# A34M41x register map
Vendor: ABOV Semiconductor Co., Ltd.; File version: 1.0
CPU: CM4 r0p1, little endian, MPU, FPU, VTOR, 4 interrupt priority bits
Registers are 32-bit, read-write, reset 0x0 unless marked. A register's access mark holds for its fields unless they carry their own. Offsets are from the block's base; [hi:lo] are bit positions; {n}, {i} and the like mark numbered series.

## CHIPCONFIG — Chip Configuration Data
Base 0x4000F000
0x00 VENDORID ro reset 0x41424F56
0x04 CHIPID ro
0x08 REVNR ro — Revision Number Register

## PA — General Port A
Base 0x40001000
Same registers: PB 0x40001100, PC 0x40001200, PD 0x40001300, PE 0x40001400, PF 0x40001500, PG 0x40001600
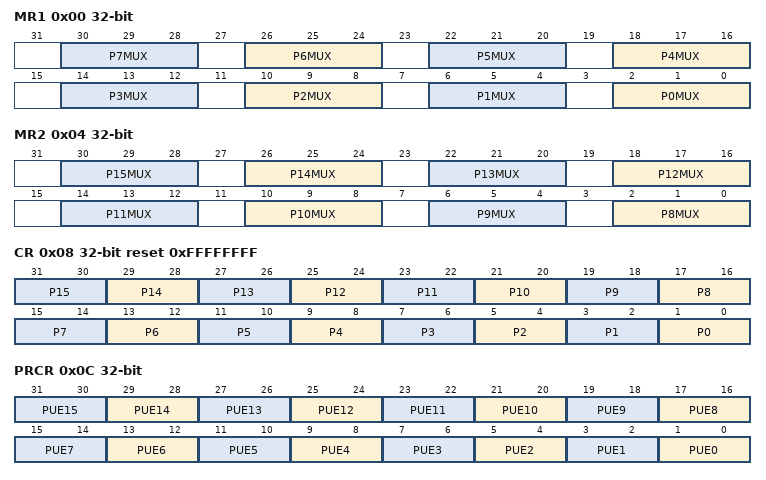
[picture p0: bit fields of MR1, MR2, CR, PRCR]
0x00 MR1 — Port n MUX1 Selection Register
  [4n+2:4n] P{n}MUX (n=0..7) — Pin {n} Mode Selection bits
0x04 MR2 — Port n MUX2 Selection Register
  [4n-30:4n-32] P{n}MUX (n=8..15) — Pin {n} Mode Selection bits
0x08 CR reset 0xFFFFFFFF — Port n Type Selection Register
  [2n+1:2n] P{n} (n=0..15) — Pin {n} Type Selection bit
0x0C PRCR — Port n Pull-up/down Selection Register
  [2n+1:2n] PUE{n} (n=0..15) — Pin {n} Pull-up/down Selection bits
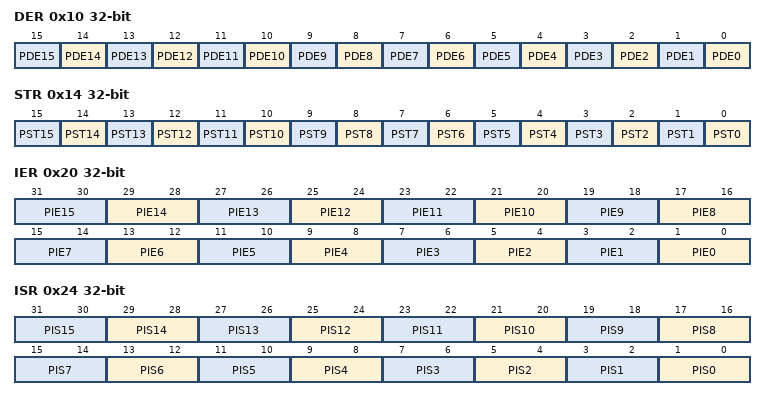
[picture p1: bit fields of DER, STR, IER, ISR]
0x10 DER — Port n Debounce Enable Register
  [n] PDE{n} (n=0..15) — Pin {n} Debounce Enable bits
0x14 STR — Port n Strength Selection Register
  [n] PST{n} (n=0..15) — Pin {n} Strength Selection bit
0x20 IER — Port n Interrupt Enable Register
  [2n+1:2n] PIE{n} (n=0..15) — Pin {n} Interrupt Enable bit
0x24 ISR — Port n Interrupt Status Register
  [2n+1:2n] PIS{n} (n=0..15) — Pin {n} Interrupt Status bit
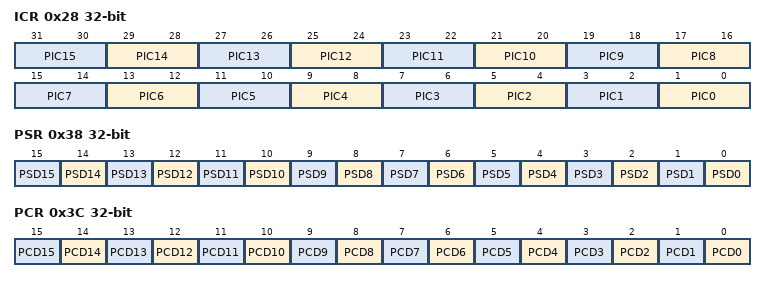
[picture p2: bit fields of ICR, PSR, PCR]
0x28 ICR — Port n Interrupt Control Register
  [2n+1:2n] PIC{n} (n=0..15) — Pin {n} Interrupt Control bit
0x30 ODR — Port n Output Data Register
  [15:0] POD — Pin Output Data bit
0x34 IDR ro — Port n Input Data Register
  [15:0] PID — Port Input Data bits
0x38 PSR wo — Port n Data Set Register
  [n] PSD{n} (n=0..15) — Port {n} Data Set bits
0x3C PCR wo — Port n Data Clear Register
  [n] PCD{n} (n=0..15) — Port {n} Data Clear bits

## PORTEN — General Port Access Enable
Base 0x40001FF0
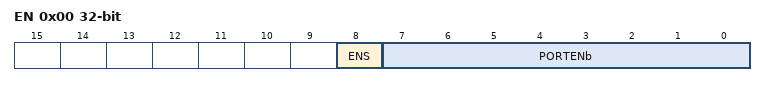
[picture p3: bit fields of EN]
0x00 EN wo (reset mask 0xFF) — Port Access Enable Register
  [8] ENS ro — Enable Status Bit
  [7:0] PORTENb — Port Access Enable bit, write sequence 0x15, 0x51

## DFMC — DATA FLASH MEMORY CONTROLLER
Base 0x41001000
0x00 CONF — Flash Memory Control Register
  [3:0] LATENCY — Flash Wait Value Bits
0x04 FLSKEY — Flash Memory Access Key Register
  [31:0] FKEY — Flash Memory Access Key, KEY1(0x01234567) -> KEY2(0x12345678) -> KEY3(0x23456789)
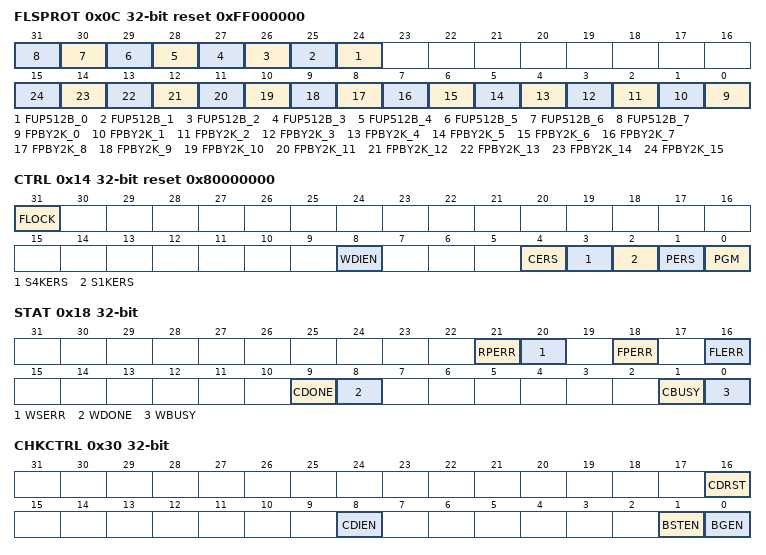
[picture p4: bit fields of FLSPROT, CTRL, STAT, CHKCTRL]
0x0C FLSPROT reset 0xFF000000 — Flash Memory Protection Register
  [n+24] FUP512B_{n} (n=0..7) — Flash upper 4KB Unprotection
  [n] FPBY2K_{n} (n=0..15) — Flash 2KB Protection
0x14 CTRL reset 0x80000000 — Flash Access Control Register
  [31] FLOCK — Flash Lock Setting Bit
  [8] WDIEN — Write done interrupt enable bit
  [4] CERS — Chip Erase Mode Bit
  [3] S4KERS — Sector 4KB Erase Mode
  [2] S1KERS — Sector 1KB Erase Mode
  [1] PERS — Page Erase Mode
  [0] PGM — Program Mode
0x18 STAT — Flash Access Status Register
  [21] RPERR — Read Protect Error(Auto Cleared)
  [20] WSERR — Write Sequence Error (Auto Cleared)
  [18] FPERR — Flash Protect Error (Auto Cleared)
  [16] FLERR — Flash Lock Error (Auto Cleared)
  [9] CDONE — Checksum Done Check (Auto Cleared)
  [8] WDONE — Write Done Check (Auto Cleared)
  [1] CBUSY ro — Checksum Busy Check
    0=Not Busy (Checksum Not Busy); 1=Busy (Checksum Busy)
  [0] WBUSY ro — Write Busy Check
    0=Not Busy (Checksum Not Busy); 1=Busy (Checksum Busy)
0x30 CHKCTRL — Flash Checksum Control Register
  [16] CDRST — Checksum Data Reset (Auto Cleared)
    0=No Effect; 1=Reset
  [8] CDIEN — Checksum Done Interrupt
    0=Disable; 1=Enable
  [1] BSTEN — Burst Mode
    0=Disable; 1=Enable
  [0] BGEN — Back Ground Mode
    0=Disable; 1=Enable
0x34 CHKDOUT — Flash Checksum Data Output Register
  [15:0] CDOUT ro — Flash Checksum Data Output bit
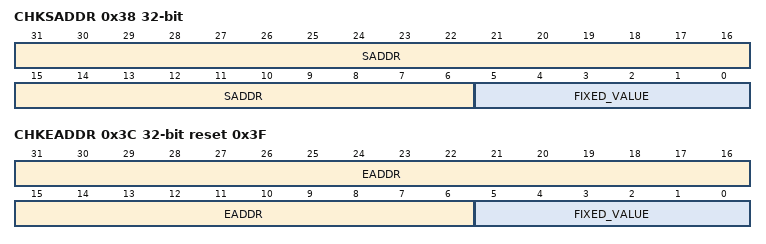
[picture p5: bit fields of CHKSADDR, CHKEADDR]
0x38 CHKSADDR — Flash Checksum Start Address Resgister
  [31:6] SADDR — Flash Checksum Start Address bit
  [5:0] FIXED_VALUE ro — Fixed Vaule
0x3C CHKEADDR reset 0x3F — Flash Checksum End Address Register
  [31:6] EADDR — Flash Checksum End Address bit
  [5:0] FIXED_VALUE ro
